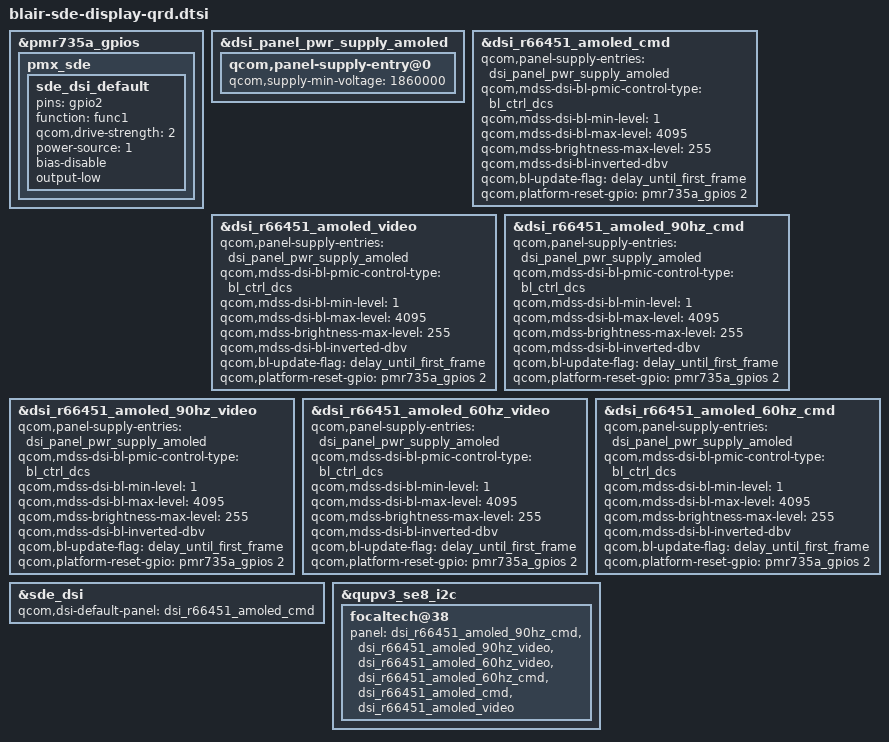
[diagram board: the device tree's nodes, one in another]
#include "blair-sde-display.dtsi"

&pmr735a_gpios {
	pmx_sde: pmx_sde {
		sde_dsi_default: sde_dsi_default {
			pins = "gpio2";
			function = "func1";
			qcom,drive-strength = <2>;
			power-source = <1>;
			bias-disable;
			output-low;
		};
	};
};

&dsi_panel_pwr_supply_amoled {
	qcom,panel-supply-entry@0 {
		qcom,supply-min-voltage = <1860000>;
	};
};

&dsi_r66451_amoled_cmd {
	qcom,panel-supply-entries = <&dsi_panel_pwr_supply_amoled>;
	qcom,mdss-dsi-bl-pmic-control-type = "bl_ctrl_dcs";
	qcom,mdss-dsi-bl-min-level = <1>;
	qcom,mdss-dsi-bl-max-level = <4095>;
	qcom,mdss-brightness-max-level = <255>;
	qcom,mdss-dsi-bl-inverted-dbv;
	qcom,bl-update-flag = "delay_until_first_frame";
	qcom,platform-reset-gpio = <&pmr735a_gpios 2 0>;
};

&dsi_r66451_amoled_video {
	qcom,panel-supply-entries = <&dsi_panel_pwr_supply_amoled>;
	qcom,mdss-dsi-bl-pmic-control-type = "bl_ctrl_dcs";
	qcom,mdss-dsi-bl-min-level = <1>;
	qcom,mdss-dsi-bl-max-level = <4095>;
	qcom,mdss-brightness-max-level = <255>;
	qcom,mdss-dsi-bl-inverted-dbv;
	qcom,bl-update-flag = "delay_until_first_frame";
	qcom,platform-reset-gpio = <&pmr735a_gpios 2 0>;
};

&dsi_r66451_amoled_90hz_cmd {
	qcom,panel-supply-entries = <&dsi_panel_pwr_supply_amoled>;
	qcom,mdss-dsi-bl-pmic-control-type = "bl_ctrl_dcs";
	qcom,mdss-dsi-bl-min-level = <1>;
	qcom,mdss-dsi-bl-max-level = <4095>;
	qcom,mdss-brightness-max-level = <255>;
	qcom,mdss-dsi-bl-inverted-dbv;
	qcom,bl-update-flag = "delay_until_first_frame";
	qcom,platform-reset-gpio = <&pmr735a_gpios 2 0>;
};

&dsi_r66451_amoled_90hz_video {
	qcom,panel-supply-entries = <&dsi_panel_pwr_supply_amoled>;
	qcom,mdss-dsi-bl-pmic-control-type = "bl_ctrl_dcs";
	qcom,mdss-dsi-bl-min-level = <1>;
	qcom,mdss-dsi-bl-max-level = <4095>;
	qcom,mdss-brightness-max-level = <255>;
	qcom,mdss-dsi-bl-inverted-dbv;
	qcom,bl-update-flag = "delay_until_first_frame";
	qcom,platform-reset-gpio = <&pmr735a_gpios 2 0>;
};

&dsi_r66451_amoled_60hz_video {
	qcom,panel-supply-entries = <&dsi_panel_pwr_supply_amoled>;
	qcom,mdss-dsi-bl-pmic-control-type = "bl_ctrl_dcs";
	qcom,mdss-dsi-bl-min-level = <1>;
	qcom,mdss-dsi-bl-max-level = <4095>;
	qcom,mdss-brightness-max-level = <255>;
	qcom,mdss-dsi-bl-inverted-dbv;
	qcom,bl-update-flag = "delay_until_first_frame";
	qcom,platform-reset-gpio = <&pmr735a_gpios 2 0>;
};

&dsi_r66451_amoled_60hz_cmd {
	qcom,panel-supply-entries = <&dsi_panel_pwr_supply_amoled>;
	qcom,mdss-dsi-bl-pmic-control-type = "bl_ctrl_dcs";
	qcom,mdss-dsi-bl-min-level = <1>;
	qcom,mdss-dsi-bl-max-level = <4095>;
	qcom,mdss-brightness-max-level = <255>;
	qcom,mdss-dsi-bl-inverted-dbv;
	qcom,bl-update-flag = "delay_until_first_frame";
	qcom,platform-reset-gpio = <&pmr735a_gpios 2 0>;
};

&sde_dsi {
	qcom,dsi-default-panel = <&dsi_r66451_amoled_cmd>;
};

&qupv3_se8_i2c {
	focaltech@38 {
		panel = <&dsi_r66451_amoled_90hz_cmd
			&dsi_r66451_amoled_90hz_video
			&dsi_r66451_amoled_60hz_video
			&dsi_r66451_amoled_60hz_cmd
			&dsi_r66451_amoled_cmd
			&dsi_r66451_amoled_video>;
	};
};
